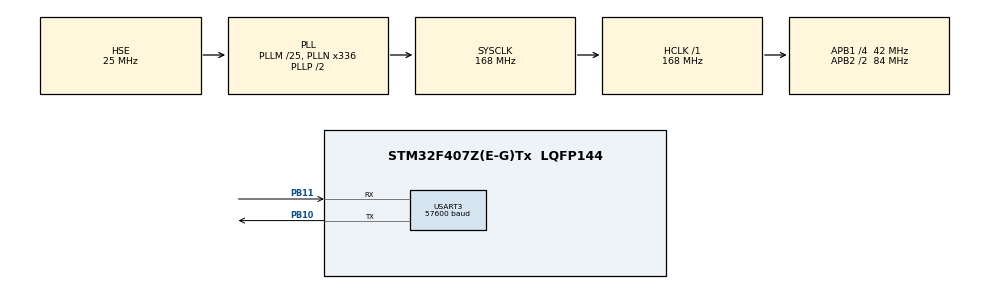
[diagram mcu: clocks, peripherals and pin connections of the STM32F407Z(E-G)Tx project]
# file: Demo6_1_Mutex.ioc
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FREERTOS.BinarySemaphores01=token,Dynamic,NULL,Available
FREERTOS.Tasks01=Task_High,40,128,AppTask_High,Default,NULL,Dynamic,NULL,NULL;Task_Middle,24,128,AppTask_Middle,Default,NULL,Dynamic,NULL,NULL;Task_Low,8,128,AppTask_Low,Default,NULL,Dynamic,NULL,NULL
FREERTOS.configUSE_NEWLIB_REENTRANT=1
Mcu.Family=STM32F4
Mcu.Name=STM32F407Z(E-G)Tx
Mcu.Package=LQFP144
NVIC.PriorityGroup=NVIC_PRIORITYGROUP_4
NVIC.TIM6_DAC_IRQn=true\:0\:0\:true\:false\:true\:false\:false\:true\:true
NVIC.TimeBase=TIM6_DAC_IRQn
NVIC.TimeBaseIP=TIM6
PA13.Mode=Serial_Wire
PA13.Signal=SYS_JTMS-SWDIO
PA14.Mode=Serial_Wire
PA14.Signal=SYS_JTCK-SWCLK
PB10.Mode=Asynchronous
PB10.Signal=USART3_TX
PB11.Mode=Asynchronous
PB11.Signal=USART3_RX
PH0-OSC_IN.Mode=HSE-External-Oscillator
PH0-OSC_IN.Signal=RCC_OSC_IN
PH1-OSC_OUT.Mode=HSE-External-Oscillator
PH1-OSC_OUT.Signal=RCC_OSC_OUT
ProjectManager.HeapSize=0x200
ProjectManager.StackSize=0x400
ProjectManager.TargetToolchain=STM32CubeIDE
RCC.48MHZClocksFreq_Value=84000000
RCC.AHBFreq_Value=168000000
RCC.APB1CLKDivider=RCC_HCLK_DIV4
RCC.APB1Freq_Value=42000000
RCC.APB1TimFreq_Value=84000000
RCC.APB2CLKDivider=RCC_HCLK_DIV2
RCC.APB2Freq_Value=84000000
RCC.APB2TimFreq_Value=168000000
RCC.CortexFreq_Value=168000000
RCC.HCLKFreq_Value=168000000
RCC.HSE_VALUE=25000000
RCC.HSI_VALUE=16000000
RCC.LSE_VALUE=32768
RCC.PLLM=25
RCC.PLLN=336
RCC.PLLSourceVirtual=RCC_PLLSOURCE_HSE
RCC.SYSCLKFreq_VALUE=168000000
RCC.SYSCLKSource=RCC_SYSCLKSOURCE_PLLCLK
RCC.VCOOutputFreq_Value=336000000
USART3.BaudRate=57600
USART3.VirtualMode=VM_ASYNC
VP_FREERTOS_VS_CMSIS_V2.Mode=CMSIS_V2
VP_SYS_VS_tim6.Mode=TIM6
board=custom

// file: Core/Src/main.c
/* USER CODE BEGIN Header */
/**
  ******************************************************************************
  * @file           : main.c
  * @brief          : Main program body
  ******************************************************************************
  * @attention
  *
  * Copyright (c) 2025 STMicroelectronics.
  * All rights reserved.
  *
  * This software is licensed under terms that can be found in the LICENSE file
  * in the root directory of this software component.
  * If no LICENSE file comes with this software, it is provided AS-IS.
  *
  ******************************************************************************
  */
/* USER CODE END Header */
#include "main.h"
#include "cmsis_os.h"
#include "usart.h"
#include "gpio.h"

/* USER CODE BEGIN Includes */
#include <stdio.h>

/* USER CODE END Includes */

/* USER CODE BEGIN PV */
//uint8_t *ascii1 =0;
//uint8_t *ascii2 =0;
/* USER CODE END PV */

void SystemClock_Config(void);
void MX_FREERTOS_Init(void);
/* USER CODE BEGIN PFP */
uint16_t HexToASCII(uint8_t data_hex);
//void uint8_to_ascii(uint8_t data, uint8_t *ascii1, uint8_t *ascii2);
/* USER CODE END PFP */

int main(void)
{

  /* MCU Configuration--------------------------------------------------------*/

  /* Reset of all peripherals, Initializes the Flash interface and the Systick. */
  HAL_Init();

  /* Configure the system clock */
  SystemClock_Config();

  /* Initialize all configured peripherals */
  MX_GPIO_Init();
  MX_USART3_UART_Init();
  /* USER CODE BEGIN 2 */
  // start menu
  uint8_t startstr[] = "Demo6_1:Priority inversion.\r\n";
  HAL_UART_Transmit(&huart3,startstr,sizeof(startstr),0xFFFF);

  uint8_t startstr1[] = "Using binary semaphore.\r\n";
  HAL_UART_Transmit(&huart3,startstr1,sizeof(startstr1),0xFFFF);

  // transmit 32bit BaudRate，process low 16b only.
  uint8_t startstr2[] = "Baud Rate = ";
  HAL_UART_Transmit(&huart3,startstr2,sizeof(startstr2),0xFFFF);

  uint16_t high8Bits = HexToASCII((huart3.Init.BaudRate>>8) & 0xFF); 		//high 8bit
  uint16_t low8Bits = HexToASCII(huart3.Init.BaudRate & 0xFF); 				//low 8bit

  HAL_UART_Transmit(&huart3,&high8Bits,2,100);										//transmit high 8 bit
  HAL_UART_Transmit(&huart3,&low8Bits,2,100);										//transmit low 8 bit

  uint8_t startstr3[] = "\r\n";
  HAL_UART_Transmit(&huart3,startstr3,sizeof(startstr3),0xFFFF);
  HAL_Delay(10);

  //or
  printf("Baud Rate = %ld.\r\n\r\n",huart3.Init.BaudRate);

  uint8_t startstr4[] = "1. Connect to PC via USART3.\r\n";
  HAL_UART_Transmit(&huart3,startstr4,sizeof(startstr4),0xFFFF);

  uint8_t startstr5[] = "2. View result on PC via ComAssistant.\r\n\r\n";
  HAL_UART_Transmit(&huart3,startstr5,sizeof(startstr5),0xFFFF);

  /* USER CODE END 2 */

  /* Init scheduler */
  osKernelInitialize();

  /* Call init function for freertos objects (in cmsis_os2.c) */
  MX_FREERTOS_Init();

  /* Start scheduler */
  osKernelStart();

  /* We should never get here as control is now taken by the scheduler */

  /* Infinite loop */
  while (1)
  {

  }
}

void SystemClock_Config(void)
{
  RCC_OscInitTypeDef RCC_OscInitStruct = {0};
  RCC_ClkInitTypeDef RCC_ClkInitStruct = {0};

  /** Configure the main internal regulator output voltage
  */
  __HAL_RCC_PWR_CLK_ENABLE();
  __HAL_PWR_VOLTAGESCALING_CONFIG(PWR_REGULATOR_VOLTAGE_SCALE1);

  /** Initializes the RCC Oscillators according to the specified parameters
  * in the RCC_OscInitTypeDef structure.
  */
  RCC_OscInitStruct.OscillatorType = RCC_OSCILLATORTYPE_HSE;
  RCC_OscInitStruct.HSEState = RCC_HSE_ON;
  RCC_OscInitStruct.PLL.PLLState = RCC_PLL_ON;
  RCC_OscInitStruct.PLL.PLLSource = RCC_PLLSOURCE_HSE;
  RCC_OscInitStruct.PLL.PLLM = 25;
  RCC_OscInitStruct.PLL.PLLN = 336;
  RCC_OscInitStruct.PLL.PLLP = RCC_PLLP_DIV2;
  RCC_OscInitStruct.PLL.PLLQ = 4;
  if (HAL_RCC_OscConfig(&RCC_OscInitStruct) != HAL_OK)
  {
    Error_Handler();
  }

  /** Initializes the CPU, AHB and APB buses clocks
  */
  RCC_ClkInitStruct.ClockType = RCC_CLOCKTYPE_HCLK|RCC_CLOCKTYPE_SYSCLK
                              |RCC_CLOCKTYPE_PCLK1|RCC_CLOCKTYPE_PCLK2;
  RCC_ClkInitStruct.SYSCLKSource = RCC_SYSCLKSOURCE_PLLCLK;
  RCC_ClkInitStruct.AHBCLKDivider = RCC_SYSCLK_DIV1;
  RCC_ClkInitStruct.APB1CLKDivider = RCC_HCLK_DIV4;
  RCC_ClkInitStruct.APB2CLKDivider = RCC_HCLK_DIV2;

  if (HAL_RCC_ClockConfig(&RCC_ClkInitStruct, FLASH_LATENCY_5) != HAL_OK)
  {
    Error_Handler();
  }
}

/* USER CODE BEGIN 4 */
int __io_putchar(int ch)
{
	HAL_UART_Transmit(&huart3,(uint8_t*)&ch,1,0xFFFF);
	return ch;
}

//将单个字节转化为两个ASCII字符进行显示，即一个字节转化为两个字节。
//如0x27，转化为'2' '7'两个字符。
uint16_t HexToASCII(uint8_t data_hex)
{
    uint8_t data_ASCII_H;
    uint8_t data_ASCII_L;
    uint16_t data_ASCII;

    data_ASCII_H = ((data_hex >> 4) & 0x0F);
    data_ASCII_L = data_hex & 0x0F;

    if(data_ASCII_H <= 9)
    {
        data_ASCII_H += 0x30;
    }
    else if((data_ASCII_H >= 10) && (data_ASCII_H <= 15))
    {
        data_ASCII_H += 0x37;
    }

    if(data_ASCII_L <= 9)
    {
        data_ASCII_L += 0x30;
    }
    else if((data_ASCII_L >= 10) && (data_ASCII_L <= 15))
    {
        data_ASCII_L += 0x37;
    }
    //HAL_UART_Transmit打印输出顺序是先低8b后高8b
    data_ASCII = (((data_ASCII_L & 0x00FF) << 8) | data_ASCII_H);

    return data_ASCII;
}

//void uint8_to_ascii(uint8_t data, uint8_t *ascii1, uint8_t *ascii2)
//{
//    uint8_t high_nibble = (data >> 4) & 0x0F;  	// 获取高四位
//    uint8_t low_nibble = data & 0x0F;          		// 获取低四位
//    // 将高四位和低四位转换为对应的 ASCII 字符
//    *ascii1 = (high_nibble <= 9) ? ('0' + high_nibble) : ('A' + (high_nibble - 10));
//    *ascii2 = (low_nibble <= 9) ? ('0' + low_nibble) : ('A' + (low_nibble - 10));
//}

/* USER CODE END 4 */

void HAL_TIM_PeriodElapsedCallback(TIM_HandleTypeDef *htim)
{
  if (htim->Instance == TIM6)
  {
    HAL_IncTick();
  }
}

void Error_Handler(void)
{
  __disable_irq();
  while (1)
  {
  }
}

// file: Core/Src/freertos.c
/* USER CODE BEGIN Header */
/**
  ******************************************************************************
  * File Name          : freertos.c
  * Description        : Code for freertos applications
  ******************************************************************************
  * @attention
  *
  * Copyright (c) 2025 STMicroelectronics.
  * All rights reserved.
  *
  * This software is licensed under terms that can be found in the LICENSE file
  * in the root directory of this software component.
  * If no LICENSE file comes with this software, it is provided AS-IS.
  *
  ******************************************************************************
  */
/* USER CODE END Header */

#include "FreeRTOS.h"
#include "task.h"
#include "main.h"
#include "cmsis_os.h"

/* USER CODE BEGIN Includes */
//#include <stdio.h>
#include "usart.h"
#include "semphr.h"
/* USER CODE END Includes */

/* Definitions for Task_High */
osThreadId_t Task_HighHandle;
const osThreadAttr_t Task_High_attributes = {
  .name = "Task_High",
  .stack_size = 128 * 4,
  .priority = (osPriority_t) osPriorityHigh,
};
/* Definitions for Task_Middle */
osThreadId_t Task_MiddleHandle;
const osThreadAttr_t Task_Middle_attributes = {
  .name = "Task_Middle",
  .stack_size = 128 * 4,
  .priority = (osPriority_t) osPriorityNormal,
};
/* Definitions for Task_Low */
osThreadId_t Task_LowHandle;
const osThreadAttr_t Task_Low_attributes = {
  .name = "Task_Low",
  .stack_size = 128 * 4,
  .priority = (osPriority_t) osPriorityLow,
};
/* Definitions for token */
osSemaphoreId_t tokenHandle;
const osSemaphoreAttr_t token_attributes = {
  .name = "token"
};

void AppTask_High(void *argument);
void AppTask_Middle(void *argument);
void AppTask_Low(void *argument);

void MX_FREERTOS_Init(void); /* (MISRA C 2004 rule 8.1) */

void MX_FREERTOS_Init(void) {

  /* Create the semaphores(s) */
  /* creation of token */
  tokenHandle = osSemaphoreNew(1, 1, &token_attributes);

  /* Create the thread(s) */
  /* creation of Task_High */
  Task_HighHandle = osThreadNew(AppTask_High, NULL, &Task_High_attributes);

  /* creation of Task_Middle */
  Task_MiddleHandle = osThreadNew(AppTask_Middle, NULL, &Task_Middle_attributes);

  /* creation of Task_Low */
  Task_LowHandle = osThreadNew(AppTask_Low, NULL, &Task_Low_attributes);

}

/* USER CODE BEGIN Header_AppTask_High */
/**
  * @brief  Function implementing the Task_High thread.
  * @param  argument: Not used
  * @retval None
  */
/**
 *  Task_High() is always waiting for the token to be received,
  * and once received,
  * it sends a message and then enters the blocking state for 500ms.
  *
 */
/* USER CODE END Header_AppTask_High */
void AppTask_High(void *argument)
{
  /* USER CODE BEGIN AppTask_High */
  /* Infinite loop */
	uint8_t strHigh[]="Task_High takes token, sends a message, then releases it.\r\n";
	for(;;)
	{
		if (xSemaphoreTake(tokenHandle, portMAX_DELAY)==pdTRUE)  //Get the semaphore.
		{
			HAL_UART_Transmit(&huart3,strHigh,sizeof(strHigh),300);
			HAL_Delay(10);								//Delay is required, otherwise the \n cannot be output normally.
			xSemaphoreGive(tokenHandle);	//Release semaphore.
		}
		vTaskDelay(500);
	}
  /* USER CODE END AppTask_High */
}

/* USER CODE BEGIN Header_AppTask_Middle */
/**
* @brief Function implementing the Task_Middle thread.
* @param argument: Not used
* @retval None
*/
/**
 * Task_Middle() is a task without parameters.
 * It naturally does not require a token to run.
 * As long as it is scheduled, it will enter the run,
 * send a message, and then enter the blocking state for 500ms.
 *
 */
/* USER CODE END Header_AppTask_Middle */
void AppTask_Middle(void *argument)
{
  /* USER CODE BEGIN AppTask_Middle */
  /* Infinite loop */
	uint8_t strMid[]="Task_Middle is running without token.\r\n";
	for(;;)
	{
		HAL_UART_Transmit(&huart3,strMid,sizeof(strMid),300);
		HAL_Delay(10);
		vTaskDelay(400);
	}
  /* USER CODE END AppTask_Middle */
}

/* USER CODE BEGIN Header_AppTask_Low */
/**
* @brief Function implementing the Task_Low thread.
* If Task_Low() gets the token, it sends a message,
* and then releases the token after 1000ms
* and enters the blocking state for 20ms.
*
* @param argument: Not used
* @retval None
*/
/* USER CODE END Header_AppTask_Low */
void AppTask_Low(void *argument)
{
  /* USER CODE BEGIN AppTask_Low */
  /* Infinite loop */
	uint8_t str1[]="Task_Low take token.\r\n";
	uint8_t str2[]="Task_Low give token.\r\n";
 	for(;;)
 	{
		if (xSemaphoreTake(tokenHandle, pdMS_TO_TICKS(200))==pdTRUE)
		{
			HAL_UART_Transmit(&huart3,str1,sizeof(str1),300);
			HAL_Delay(1000);	//Continuous delay, but no semaphore is released, and the task will be preempted by Task_Middle during this period.
			HAL_UART_Transmit(&huart3,str2,sizeof(str2),300);
			HAL_Delay(10);
			xSemaphoreGive(tokenHandle);
		}
		vTaskDelay(20);
 	}

  /* USER CODE END AppTask_Low */
}
